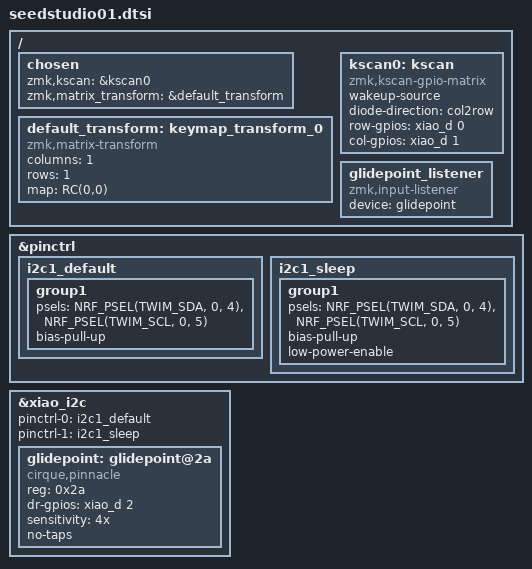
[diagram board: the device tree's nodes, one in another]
/*
 * Copyright (c) 2020 The ZMK Contributors
 *
 * SPDX-License-Identifier: MIT
 */

#include <dt-bindings/zmk/matrix_transform.h>
#include <dt-bindings/zmk/input_transform.h>
#include <input/processors.dtsi>

/ {
    chosen {
        zmk,kscan = &kscan0;
        zmk,matrix_transform = &default_transform;
    };

    default_transform: keymap_transform_0 {
        compatible = "zmk,matrix-transform";
        columns = <1>;
        rows = <1>;
        map = <RC(0,0)>;
    };

    kscan0: kscan {
        compatible = "zmk,kscan-gpio-matrix";
        wakeup-source;

        diode-direction = "col2row";
        row-gpios
            = <&xiao_d 0 (GPIO_ACTIVE_HIGH | GPIO_PULL_DOWN)>
            ;
        col-gpios
            = <&xiao_d 1 GPIO_ACTIVE_HIGH>
            ;
    };

    glidepoint_listener: glidepoint_listener {
        compatible = "zmk,input-listener";
        status = "okay";
        device = <&glidepoint>;
    };
};

&pinctrl {
	i2c1_default: i2c1_default {
		group1 {
			psels = <NRF_PSEL(TWIM_SDA, 0, 4)>,
				<NRF_PSEL(TWIM_SCL, 0, 5)>;
            bias-pull-up;
		};
	};

	i2c1_sleep: i2c1_sleep {
		group1 {
			psels = <NRF_PSEL(TWIM_SDA, 0, 4)>,
				<NRF_PSEL(TWIM_SCL, 0, 5)>;
            bias-pull-up;
			low-power-enable;
		};
	};
};

// CirqueTrackPad on I2C
&xiao_i2c {
    pinctrl-0 = <&i2c1_default>;
    pinctrl-1 = <&i2c1_sleep>;
    pinctrl-names = "default", "sleep";
    status = "okay";

    glidepoint: glidepoint@2a {
        compatible = "cirque,pinnacle";
        reg = <0x2a>;
        status = "okay";
        dr-gpios = <&xiao_d 2 (GPIO_ACTIVE_HIGH)>;

        sensitivity = "4x";
        //sleep; 
        no-taps;
    };
};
